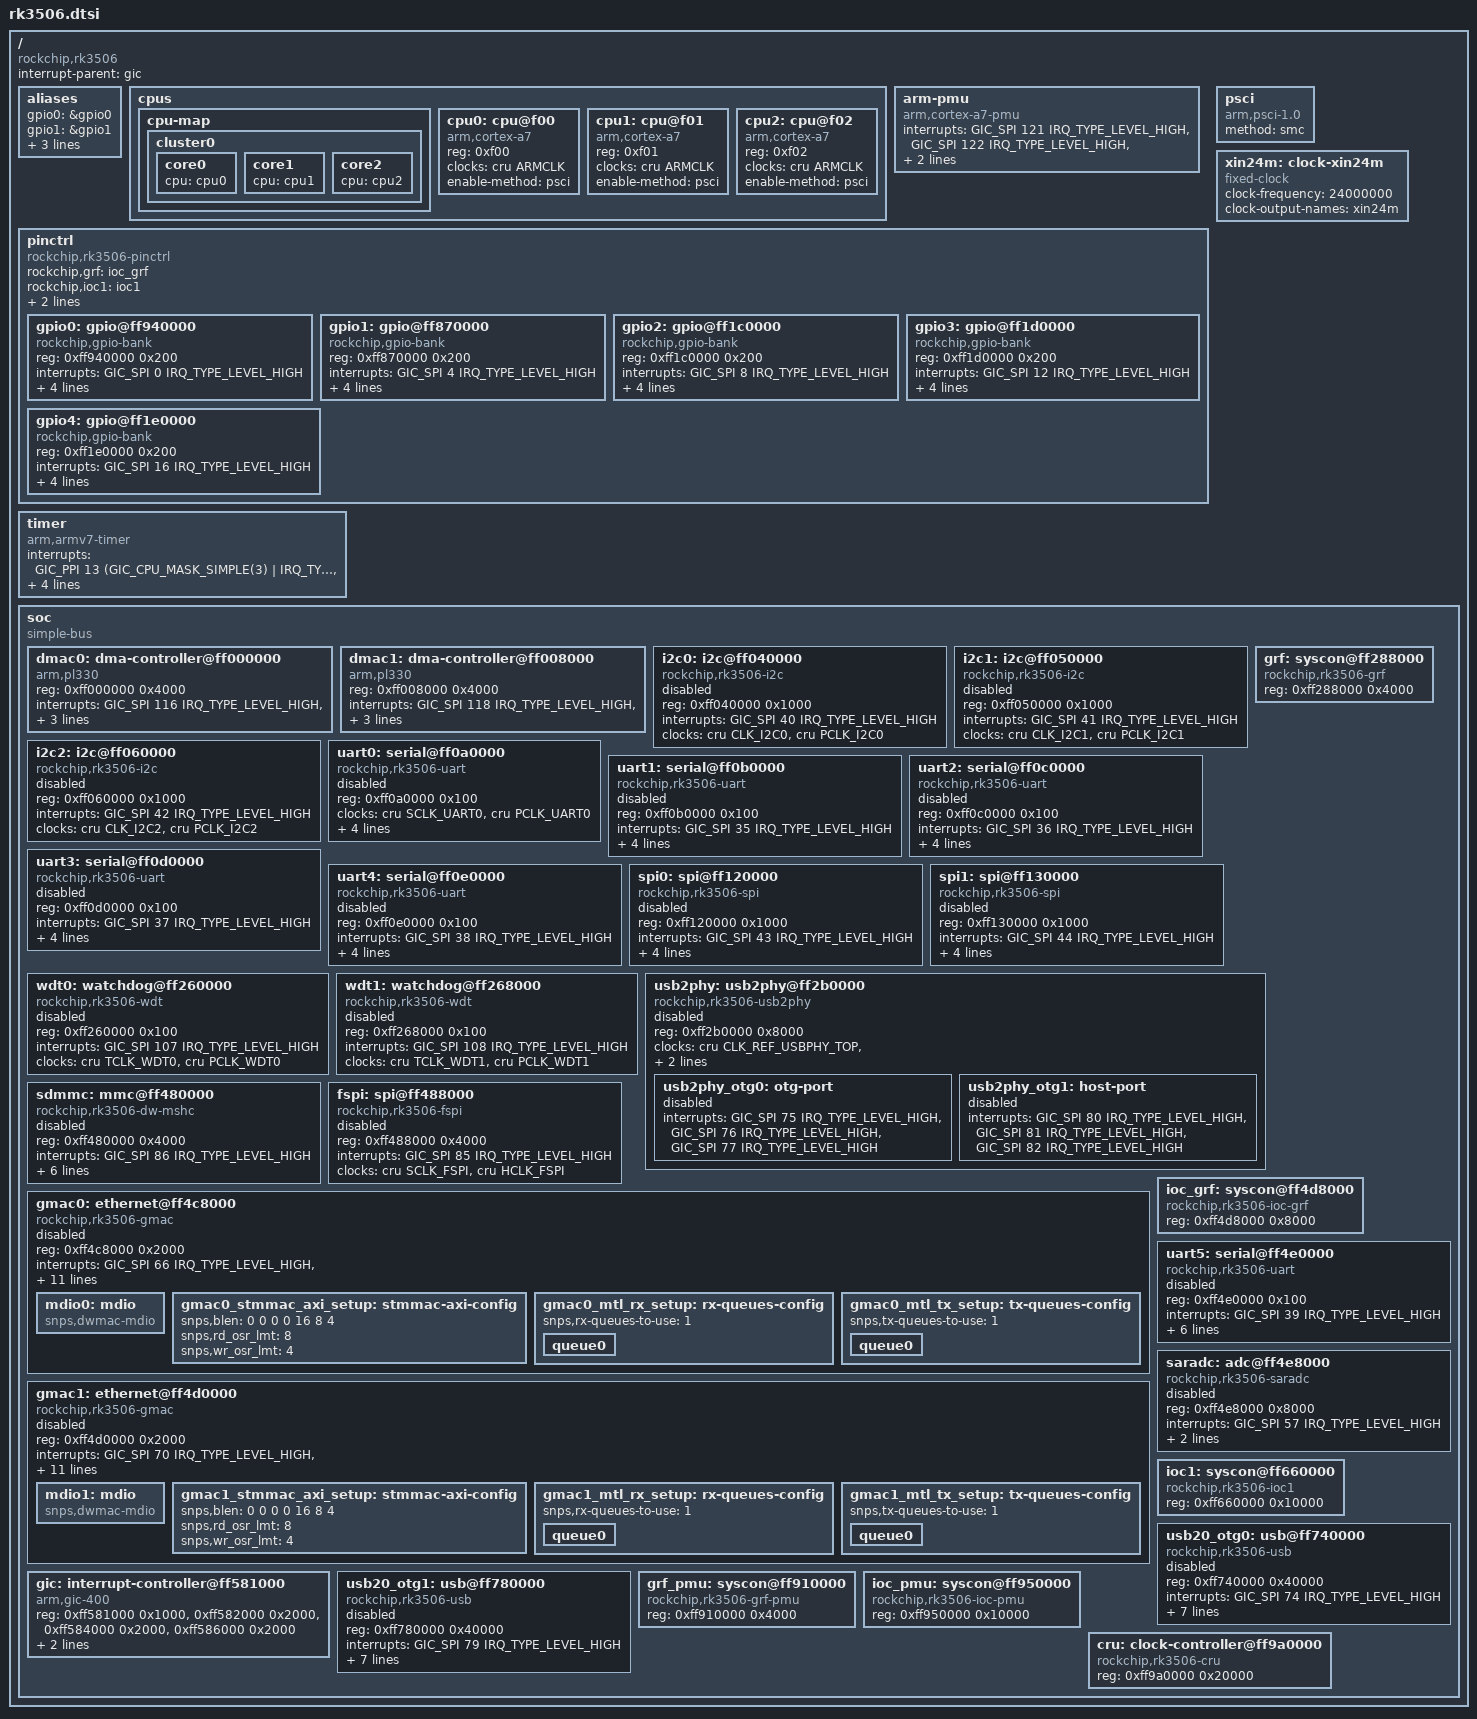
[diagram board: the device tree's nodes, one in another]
// SPDX-License-Identifier: (GPL-2.0+ OR MIT)

#include <dt-bindings/clock/rk3506-cru.h>
#include <dt-bindings/gpio/gpio.h>
#include <dt-bindings/interrupt-controller/arm-gic.h>

/ {
	compatible = "rockchip,rk3506";

	interrupt-parent = <&gic>;
	#address-cells = <1>;
	#size-cells = <1>;

	aliases {
		gpio0 = &gpio0;
		gpio1 = &gpio1;
		gpio2 = &gpio2;
		gpio3 = &gpio3;
		gpio4 = &gpio4;
	};

	cpus {
		#address-cells = <1>;
		#size-cells = <0>;

		cpu-map {
			cluster0 {
				core0 {
					cpu = <&cpu0>;
				};
				core1 {
					cpu = <&cpu1>;
				};
				core2 {
					cpu = <&cpu2>;
				};
			};
		};

		cpu0: cpu@f00 {
			compatible = "arm,cortex-a7";
			reg = <0xf00>;
			clocks = <&cru ARMCLK>;
			device_type = "cpu";
			enable-method = "psci";
		};

		cpu1: cpu@f01 {
			compatible = "arm,cortex-a7";
			reg = <0xf01>;
			clocks = <&cru ARMCLK>;
			device_type = "cpu";
			enable-method = "psci";
		};

		cpu2: cpu@f02 {
			compatible = "arm,cortex-a7";
			reg = <0xf02>;
			clocks = <&cru ARMCLK>;
			device_type = "cpu";
			enable-method = "psci";
		};
	};

	arm-pmu {
		compatible = "arm,cortex-a7-pmu";
		interrupts = <GIC_SPI 121 IRQ_TYPE_LEVEL_HIGH>,
			     <GIC_SPI 122 IRQ_TYPE_LEVEL_HIGH>,
			     <GIC_SPI 123 IRQ_TYPE_LEVEL_HIGH>;
		interrupt-affinity = <&cpu0>, <&cpu1>, <&cpu2>;
	};

	pinctrl: pinctrl {
		compatible = "rockchip,rk3506-pinctrl";
		rockchip,grf = <&ioc_grf>;
		rockchip,ioc1 = <&ioc1>;
		rockchip,pmu = <&ioc_pmu>;
		rockchip,rmio = <&grf_pmu>;
		#address-cells = <1>;
		#size-cells = <1>;
		ranges;

		gpio0: gpio@ff940000 {
			compatible = "rockchip,gpio-bank";
			reg = <0xff940000 0x200>;
			interrupts = <GIC_SPI 0 IRQ_TYPE_LEVEL_HIGH>;
			clocks = <&cru PCLK_GPIO0>, <&cru DBCLK_GPIO0>;
			gpio-controller;
			#gpio-cells = <2>;
			gpio-ranges = <&pinctrl 0 0 32>;
			interrupt-controller;
			#interrupt-cells = <2>;
		};

		gpio1: gpio@ff870000 {
			compatible = "rockchip,gpio-bank";
			reg = <0xff870000 0x200>;
			interrupts = <GIC_SPI 4 IRQ_TYPE_LEVEL_HIGH>;
			clocks = <&cru PCLK_GPIO1>, <&cru DBCLK_GPIO1>;
			gpio-controller;
			#gpio-cells = <2>;
			gpio-ranges = <&pinctrl 0 32 32>;
			interrupt-controller;
			#interrupt-cells = <2>;
		};

		gpio2: gpio@ff1c0000 {
			compatible = "rockchip,gpio-bank";
			reg = <0xff1c0000 0x200>;
			interrupts = <GIC_SPI 8 IRQ_TYPE_LEVEL_HIGH>;
			clocks = <&cru PCLK_GPIO2>, <&cru DBCLK_GPIO2>;
			gpio-controller;
			#gpio-cells = <2>;
			gpio-ranges = <&pinctrl 0 64 32>;
			interrupt-controller;
			#interrupt-cells = <2>;
		};

		gpio3: gpio@ff1d0000 {
			compatible = "rockchip,gpio-bank";
			reg = <0xff1d0000 0x200>;
			interrupts = <GIC_SPI 12 IRQ_TYPE_LEVEL_HIGH>;
			clocks = <&cru PCLK_GPIO3>, <&cru DBCLK_GPIO3>;
			gpio-controller;
			#gpio-cells = <2>;
			gpio-ranges = <&pinctrl 0 96 32>;
			interrupt-controller;
			#interrupt-cells = <2>;
		};

		gpio4: gpio@ff1e0000 {
			compatible = "rockchip,gpio-bank";
			reg = <0xff1e0000 0x200>;
			interrupts = <GIC_SPI 16 IRQ_TYPE_LEVEL_HIGH>;
			clocks = <&cru PCLK_GPIO4>, <&cru DBCLK_GPIO4>;
			gpio-controller;
			#gpio-cells = <2>;
			gpio-ranges = <&pinctrl 0 128 32>;
			interrupt-controller;
			#interrupt-cells = <2>;
		};
	};

	psci {
		compatible = "arm,psci-1.0", "arm,psci-0.2";
		method = "smc";
	};

	timer {
		compatible = "arm,armv7-timer";
		interrupts = <GIC_PPI 13 (GIC_CPU_MASK_SIMPLE(3) | IRQ_TYPE_LEVEL_HIGH)>,
			     <GIC_PPI 14 (GIC_CPU_MASK_SIMPLE(3) | IRQ_TYPE_LEVEL_HIGH)>,
			     <GIC_PPI 11 (GIC_CPU_MASK_SIMPLE(3) | IRQ_TYPE_LEVEL_HIGH)>,
			     <GIC_PPI 10 (GIC_CPU_MASK_SIMPLE(3) | IRQ_TYPE_LEVEL_HIGH)>;
		clock-frequency = <24000000>;
	};

	xin24m: clock-xin24m {
		compatible = "fixed-clock";
		clock-frequency = <24000000>;
		clock-output-names = "xin24m";
		#clock-cells = <0>;
	};

	soc {
		compatible = "simple-bus";
		ranges = <0xff000000 0xff000000 0x1000000>;
		#address-cells = <1>;
		#size-cells = <1>;

		dmac0: dma-controller@ff000000 {
			compatible = "arm,pl330", "arm,primecell";
			reg = <0xff000000 0x4000>;
			interrupts = <GIC_SPI 116 IRQ_TYPE_LEVEL_HIGH>,
				     <GIC_SPI 117 IRQ_TYPE_LEVEL_HIGH>;
			clocks = <&cru ACLK_DMAC0>;
			clock-names = "apb_pclk";
			#dma-cells = <1>;
			arm,pl330-periph-burst;
		};

		dmac1: dma-controller@ff008000 {
			compatible = "arm,pl330", "arm,primecell";
			reg = <0xff008000 0x4000>;
			interrupts = <GIC_SPI 118 IRQ_TYPE_LEVEL_HIGH>,
				     <GIC_SPI 119 IRQ_TYPE_LEVEL_HIGH>;
			clocks = <&cru ACLK_DMAC1>;
			clock-names = "apb_pclk";
			#dma-cells = <1>;
			arm,pl330-periph-burst;
		};

		i2c0: i2c@ff040000 {
			compatible = "rockchip,rk3506-i2c", "rockchip,rk3399-i2c";
			reg = <0xff040000 0x1000>;
			interrupts = <GIC_SPI 40 IRQ_TYPE_LEVEL_HIGH>;
			clocks = <&cru CLK_I2C0>, <&cru PCLK_I2C0>;
			clock-names = "i2c", "pclk";
			#address-cells = <1>;
			#size-cells = <0>;
			status = "disabled";
		};

		i2c1: i2c@ff050000 {
			compatible = "rockchip,rk3506-i2c", "rockchip,rk3399-i2c";
			reg = <0xff050000 0x1000>;
			interrupts = <GIC_SPI 41 IRQ_TYPE_LEVEL_HIGH>;
			clocks = <&cru CLK_I2C1>, <&cru PCLK_I2C1>;
			clock-names = "i2c", "pclk";
			#address-cells = <1>;
			#size-cells = <0>;
			status = "disabled";
		};

		i2c2: i2c@ff060000 {
			compatible = "rockchip,rk3506-i2c", "rockchip,rk3399-i2c";
			reg = <0xff060000 0x1000>;
			interrupts = <GIC_SPI 42 IRQ_TYPE_LEVEL_HIGH>;
			clocks = <&cru CLK_I2C2>, <&cru PCLK_I2C2>;
			clock-names = "i2c", "pclk";
			#address-cells = <1>;
			#size-cells = <0>;
			status = "disabled";
		};

		uart0: serial@ff0a0000 {
			compatible = "rockchip,rk3506-uart", "snps,dw-apb-uart";
			reg = <0xff0a0000 0x100>;
			clocks = <&cru SCLK_UART0>, <&cru PCLK_UART0>;
			clock-names = "baudclk", "apb_pclk";
			dmas = <&dmac0 4>, <&dmac0 5>;
			pinctrl-names = "default";
			pinctrl-0 = <&uart0_xfer>;
			reg-io-width = <4>;
			reg-shift = <2>;
			status = "disabled";
		};

		uart1: serial@ff0b0000 {
			compatible = "rockchip,rk3506-uart", "snps,dw-apb-uart";
			reg = <0xff0b0000 0x100>;
			interrupts = <GIC_SPI 35 IRQ_TYPE_LEVEL_HIGH>;
			clocks = <&cru SCLK_UART1>, <&cru PCLK_UART1>;
			clock-names = "baudclk", "apb_pclk";
			dmas = <&dmac0 6>, <&dmac0 7>;
			reg-io-width = <4>;
			reg-shift = <2>;
			status = "disabled";
		};

		uart2: serial@ff0c0000 {
			compatible = "rockchip,rk3506-uart", "snps,dw-apb-uart";
			reg = <0xff0c0000 0x100>;
			interrupts = <GIC_SPI 36 IRQ_TYPE_LEVEL_HIGH>;
			clocks = <&cru SCLK_UART2>, <&cru PCLK_UART2>;
			clock-names = "baudclk", "apb_pclk";
			dmas = <&dmac0 8>, <&dmac0 9>;
			reg-io-width = <4>;
			reg-shift = <2>;
			status = "disabled";
		};

		uart3: serial@ff0d0000 {
			compatible = "rockchip,rk3506-uart", "snps,dw-apb-uart";
			reg = <0xff0d0000 0x100>;
			interrupts = <GIC_SPI 37 IRQ_TYPE_LEVEL_HIGH>;
			clocks = <&cru SCLK_UART3>, <&cru PCLK_UART3>;
			clock-names = "baudclk", "apb_pclk";
			dmas = <&dmac0 10>, <&dmac0 11>;
			reg-io-width = <4>;
			reg-shift = <2>;
			status = "disabled";
		};

		uart4: serial@ff0e0000 {
			compatible = "rockchip,rk3506-uart", "snps,dw-apb-uart";
			reg = <0xff0e0000 0x100>;
			interrupts = <GIC_SPI 38 IRQ_TYPE_LEVEL_HIGH>;
			clocks = <&cru SCLK_UART4>, <&cru PCLK_UART4>;
			clock-names = "baudclk", "apb_pclk";
			dmas = <&dmac1 12>, <&dmac1 13>;
			reg-io-width = <4>;
			reg-shift = <2>;
			status = "disabled";
		};

		spi0: spi@ff120000 {
			compatible = "rockchip,rk3506-spi", "rockchip,rk3066-spi";
			reg = <0xff120000 0x1000>;
			interrupts = <GIC_SPI 43 IRQ_TYPE_LEVEL_HIGH>;
			clocks = <&cru CLK_SPI0>, <&cru PCLK_SPI0>;
			clock-names = "spiclk", "apb_pclk";
			dmas = <&dmac0 0>, <&dmac0 1>;
			dma-names = "tx", "rx";
			num-cs = <2>;
			pinctrl-names = "default";
			pinctrl-0 = <&spi0_csn0>, <&spi0_csn1>, <&spi0_clk>;
			#address-cells = <1>;
			#size-cells = <0>;
			status = "disabled";
		};

		spi1: spi@ff130000 {
			compatible = "rockchip,rk3506-spi", "rockchip,rk3066-spi";
			reg = <0xff130000 0x1000>;
			interrupts = <GIC_SPI 44 IRQ_TYPE_LEVEL_HIGH>;
			clocks = <&cru CLK_SPI1>, <&cru PCLK_SPI1>;
			clock-names = "spiclk", "apb_pclk";
			dmas = <&dmac0 2>, <&dmac0 3>;
			dma-names = "tx", "rx";
			num-cs = <2>;
			pinctrl-names = "default";
			pinctrl-0 = <&spi1_csn0>, <&spi1_csn1>, <&spi1_clk>;
			#address-cells = <1>;
			#size-cells = <0>;
			status = "disabled";
		};

		wdt0: watchdog@ff260000 {
			compatible = "rockchip,rk3506-wdt", "snps,dw-wdt";
			reg = <0xff260000 0x100>;
			interrupts = <GIC_SPI 107 IRQ_TYPE_LEVEL_HIGH>;
			clocks = <&cru TCLK_WDT0>, <&cru PCLK_WDT0>;
			clock-names = "tclk", "pclk";
			status = "disabled";
		};

		wdt1: watchdog@ff268000 {
			compatible = "rockchip,rk3506-wdt", "snps,dw-wdt";
			reg = <0xff268000 0x100>;
			interrupts = <GIC_SPI 108 IRQ_TYPE_LEVEL_HIGH>;
			clocks = <&cru TCLK_WDT1>, <&cru PCLK_WDT1>;
			clock-names = "tclk", "pclk";
			status = "disabled";
		};

		grf: syscon@ff288000 {
			compatible = "rockchip,rk3506-grf", "syscon", "simple-mfd";
			reg = <0xff288000 0x4000>;
		};

		usb2phy: usb2phy@ff2b0000 {
			compatible = "rockchip,rk3506-usb2phy";
			reg = <0xff2b0000 0x8000>;
			clocks = <&cru CLK_REF_USBPHY_TOP>, <&cru PCLK_USBPHY>;
			clock-names = "phyclk", "apb_pclk";
			#clock-cells = <0>;
			rockchip,usbgrf = <&grf>;
			status = "disabled";

			usb2phy_otg0: otg-port {
				interrupts = <GIC_SPI 75 IRQ_TYPE_LEVEL_HIGH>,
					     <GIC_SPI 76 IRQ_TYPE_LEVEL_HIGH>,
					     <GIC_SPI 77 IRQ_TYPE_LEVEL_HIGH>;
				interrupt-names = "otg-bvalid",
						  "otg-id",
						  "linestate";
				#phy-cells = <0>;
				status = "disabled";
			};

			usb2phy_otg1: host-port {
				interrupts = <GIC_SPI 80 IRQ_TYPE_LEVEL_HIGH>,
					     <GIC_SPI 81 IRQ_TYPE_LEVEL_HIGH>,
					     <GIC_SPI 82 IRQ_TYPE_LEVEL_HIGH>;
				interrupt-names = "otg-bvalid",
						  "otg-id",
						  "linestate";
				#phy-cells = <0>;
				status = "disabled";
			};
		};

		sdmmc: mmc@ff480000 {
			compatible = "rockchip,rk3506-dw-mshc",
				     "rockchip,rk3288-dw-mshc";
			reg = <0xff480000 0x4000>;
			interrupts = <GIC_SPI 86 IRQ_TYPE_LEVEL_HIGH>;
			bus-width = <4>;
			clocks = <&cru HCLK_SDMMC>, <&cru CCLK_SRC_SDMMC>;
			clock-names = "biu", "ciu";
			fifo-depth = <0x100>;
			max-frequency = <150000000>;
			pinctrl-names = "default";
			pinctrl-0 = <&sdmmc_bus4>, <&sdmmc_clk>, <&sdmmc_cmd>;
			resets = <&cru SRST_H_SDMMC>;
			reset-names = "reset";
			status = "disabled";
		};

		fspi: spi@ff488000 {
			compatible = "rockchip,rk3506-fspi", "rockchip,sfc";
			reg = <0xff488000 0x4000>;
			interrupts = <GIC_SPI 85 IRQ_TYPE_LEVEL_HIGH>;
			clocks = <&cru SCLK_FSPI>, <&cru HCLK_FSPI>;
			clock-names = "clk_sfc", "hclk_sfc";
			#address-cells = <1>;
			#size-cells = <0>;
			status = "disabled";
		};

		gmac0: ethernet@ff4c8000 {
			compatible = "rockchip,rk3506-gmac", "snps,dwmac-4.20a";
			reg = <0xff4c8000 0x2000>;
			interrupts = <GIC_SPI 66 IRQ_TYPE_LEVEL_HIGH>,
				     <GIC_SPI 69 IRQ_TYPE_LEVEL_HIGH>;
			interrupt-names = "macirq", "eth_wake_irq";
			clocks = <&cru CLK_MAC0>, <&cru CLK_MAC0_PTP>,
				 <&cru PCLK_MAC0>, <&cru ACLK_MAC0>;
			clock-names = "stmmaceth", "ptp_ref",
				      "pclk_mac", "aclk_mac";
			phy-mode = "rmii";
			resets = <&cru SRST_A_MAC0>;
			reset-names = "stmmaceth";
			rockchip,grf = <&grf>;
			snps,axi-config = <&gmac0_stmmac_axi_setup>;
			snps,mixed-burst;
			snps,mtl-rx-config = <&gmac0_mtl_rx_setup>;
			snps,mtl-tx-config = <&gmac0_mtl_tx_setup>;
			snps,tso;
			status = "disabled";

			mdio0: mdio {
				compatible = "snps,dwmac-mdio";
				#address-cells = <0x1>;
				#size-cells = <0x0>;
			};

			gmac0_stmmac_axi_setup: stmmac-axi-config {
				snps,blen = <0 0 0 0 16 8 4>;
				snps,rd_osr_lmt = <8>;
				snps,wr_osr_lmt = <4>;
			};

			gmac0_mtl_rx_setup: rx-queues-config {
				snps,rx-queues-to-use = <1>;
				queue0 {};
			};

			gmac0_mtl_tx_setup: tx-queues-config {
				snps,tx-queues-to-use = <1>;
				queue0 {};
			};
		};

		ioc_grf: syscon@ff4d8000 {
			compatible = "rockchip,rk3506-ioc-grf", "syscon";
			reg = <0xff4d8000 0x8000>;
		};

		gmac1: ethernet@ff4d0000 {
			compatible = "rockchip,rk3506-gmac", "snps,dwmac-4.20a";
			reg = <0xff4d0000 0x2000>;
			interrupts = <GIC_SPI 70 IRQ_TYPE_LEVEL_HIGH>,
				     <GIC_SPI 73 IRQ_TYPE_LEVEL_HIGH>;
			interrupt-names = "macirq", "eth_wake_irq";
			clocks = <&cru CLK_MAC1>, <&cru CLK_MAC1_PTP>,
				 <&cru PCLK_MAC1>, <&cru ACLK_MAC1>;
			clock-names = "stmmaceth", "ptp_ref",
				      "pclk_mac", "aclk_mac";
			phy-mode = "rmii";
			resets = <&cru SRST_A_MAC1>;
			reset-names = "stmmaceth";
			rockchip,grf = <&grf>;
			snps,axi-config = <&gmac1_stmmac_axi_setup>;
			snps,mixed-burst;
			snps,mtl-rx-config = <&gmac1_mtl_rx_setup>;
			snps,mtl-tx-config = <&gmac1_mtl_tx_setup>;
			snps,tso;
			status = "disabled";

			mdio1: mdio {
				compatible = "snps,dwmac-mdio";
				#address-cells = <0x1>;
				#size-cells = <0x0>;
			};

			gmac1_stmmac_axi_setup: stmmac-axi-config {
				snps,blen = <0 0 0 0 16 8 4>;
				snps,rd_osr_lmt = <8>;
				snps,wr_osr_lmt = <4>;
			};

			gmac1_mtl_rx_setup: rx-queues-config {
				snps,rx-queues-to-use = <1>;
				queue0 {};
			};

			gmac1_mtl_tx_setup: tx-queues-config {
				snps,tx-queues-to-use = <1>;
				queue0 {};
			};
		};

		uart5: serial@ff4e0000 {
			compatible = "rockchip,rk3506-uart", "snps,dw-apb-uart";
			reg = <0xff4e0000 0x100>;
			interrupts = <GIC_SPI 39 IRQ_TYPE_LEVEL_HIGH>;
			clocks = <&cru SCLK_UART5>, <&cru PCLK_UART5>;
			clock-names = "baudclk", "apb_pclk";
			dmas = <&dmac1 14>, <&dmac1 15>;
			pinctrl-names = "default";
			pinctrl-0 = <&uart5m0_xfer>, <&uart5m0_ctsn>, <&uart5m0_rtsn>;
			reg-io-width = <4>;
			reg-shift = <2>;
			status = "disabled";
		};

		saradc: adc@ff4e8000 {
			compatible = "rockchip,rk3506-saradc",
				     "rockchip,rk3528-saradc";
			reg = <0xff4e8000 0x8000>;
			interrupts = <GIC_SPI 57 IRQ_TYPE_LEVEL_HIGH>;
			#io-channel-cells = <1>;
			clocks = <&cru CLK_SARADC>, <&cru PCLK_SARADC>;
			clock-names = "saradc", "apb_pclk";
			resets = <&cru SRST_P_SARADC>;
			reset-names = "saradc-apb";
			status = "disabled";
		};

		gic: interrupt-controller@ff581000 {
			compatible = "arm,gic-400";
			reg = <0xff581000 0x1000>,
			      <0xff582000 0x2000>,
			      <0xff584000 0x2000>,
			      <0xff586000 0x2000>;
			interrupts = <GIC_PPI 9 IRQ_TYPE_LEVEL_HIGH>;
			interrupt-controller;
			#interrupt-cells = <3>;
			#address-cells = <0>;
		};

		ioc1: syscon@ff660000 {
			compatible = "rockchip,rk3506-ioc1", "syscon";
			reg = <0xff660000 0x10000>;
		};

		usb20_otg0: usb@ff740000 {
			compatible = "rockchip,rk3506-usb",
				     "rockchip,rk3066-usb", "snps,dwc2";
			reg = <0xff740000 0x40000>;
			interrupts = <GIC_SPI 74 IRQ_TYPE_LEVEL_HIGH>;
			clocks = <&cru HCLK_USBOTG0>, <&cru HCLK_USBOTG0_PMU>,
				 <&cru CLK_USBOTG0_ADP>;
			clock-names = "otg", "pmu", "adp";
			dr_mode = "otg";
			phys = <&usb2phy_otg0>;
			phy-names = "usb2-phy";
			g-np-tx-fifo-size = <16>;
			g-rx-fifo-size = <280>;
			g-tx-fifo-size = <256 128 128 64 32 16>;
			status = "disabled";
		};

		usb20_otg1: usb@ff780000 {
			compatible = "rockchip,rk3506-usb",
				     "rockchip,rk3066-usb", "snps,dwc2";
			reg = <0xff780000 0x40000>;
			interrupts = <GIC_SPI 79 IRQ_TYPE_LEVEL_HIGH>;
			clocks = <&cru HCLK_USBOTG1>, <&cru HCLK_USBOTG1_PMU>,
				 <&cru CLK_USBOTG1_ADP>;
			clock-names = "otg", "pmu", "adp";
			dr_mode = "otg";
			phys = <&usb2phy_otg1>;
			phy-names = "usb2-phy";
			g-np-tx-fifo-size = <16>;
			g-rx-fifo-size = <280>;
			g-tx-fifo-size = <256 128 128 64 32 16>;
			status = "disabled";
		};

		grf_pmu: syscon@ff910000 {
			compatible = "rockchip,rk3506-grf-pmu", "syscon", "simple-mfd";
			reg = <0xff910000 0x4000>;
		};

		ioc_pmu: syscon@ff950000 {
			compatible = "rockchip,rk3506-ioc-pmu", "syscon";
			reg = <0xff950000 0x10000>;
		};

		cru: clock-controller@ff9a0000 {
			compatible = "rockchip,rk3506-cru";
			reg = <0xff9a0000 0x20000>;
			#clock-cells = <1>;
			#reset-cells = <1>;
		};
	};
};

#include "rk3506-pinctrl.dtsi"
